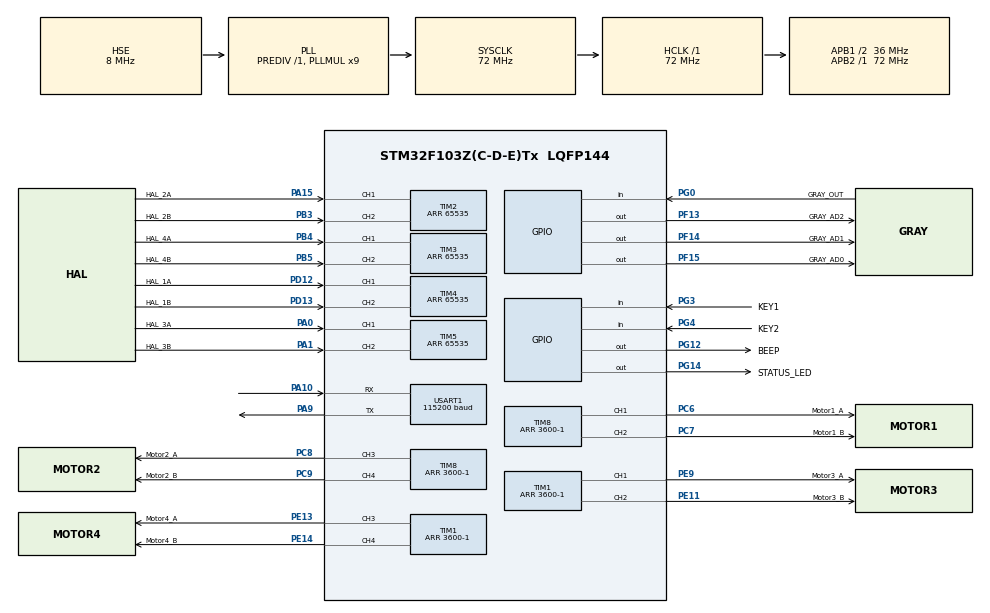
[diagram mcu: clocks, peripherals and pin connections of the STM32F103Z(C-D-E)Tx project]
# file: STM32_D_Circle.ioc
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Mcu.Family=STM32F1
Mcu.Name=STM32F103Z(C-D-E)Tx
Mcu.Package=LQFP144
NVIC.PriorityGroup=NVIC_PRIORITYGROUP_4
NVIC.USART1_IRQn=true\:1\:0\:false\:false\:true\:true\:true\:true
OSC_IN.Mode=HSE-External-Oscillator
OSC_IN.Signal=RCC_OSC_IN
OSC_OUT.Mode=HSE-External-Oscillator
OSC_OUT.Signal=RCC_OSC_OUT
PA0-WKUP.GPIO_Label=HAL_3A
PA0-WKUP.Signal=S_TIM5_CH1
PA1.GPIO_Label=HAL_3B
PA1.Signal=S_TIM5_CH2
PA10.Mode=Asynchronous
PA10.Signal=USART1_RX
PA13.Mode=Serial_Wire
PA13.Signal=SYS_JTMS-SWDIO
PA14.Mode=Serial_Wire
PA14.Signal=SYS_JTCK-SWCLK
PA15.GPIO_Label=HAL_2A
PA15.Signal=S_TIM2_CH1_ETR
PA9.Mode=Asynchronous
PA9.Signal=USART1_TX
PB3.GPIO_Label=HAL_2B
PB3.Signal=S_TIM2_CH2
PB4.GPIO_Label=HAL_4A
PB4.Signal=S_TIM3_CH1
PB5.GPIO_Label=HAL_4B
PB5.Signal=S_TIM3_CH2
PC6.GPIO_Label=Motor1_A
PC6.Signal=S_TIM8_CH1
PC7.GPIO_Label=Motor1_B
PC7.Signal=S_TIM8_CH2
PC8.GPIO_Label=Motor2_A
PC8.Signal=S_TIM8_CH3
PC9.GPIO_Label=Motor2_B
PC9.Signal=S_TIM8_CH4
PD12.GPIO_Label=HAL_1A
PD12.Signal=S_TIM4_CH1
PD13.GPIO_Label=HAL_1B
PD13.Signal=S_TIM4_CH2
PE11.GPIO_Label=Motor3_B
PE11.Signal=S_TIM1_CH2
PE13.GPIO_Label=Motor4_A
PE13.Signal=S_TIM1_CH3
PE14.GPIO_Label=Motor4_B
PE14.Signal=S_TIM1_CH4
PE9.GPIO_Label=Motor3_A
PE9.Signal=S_TIM1_CH1
PF13.GPIO_Label=GRAY_AD2
PF13.Signal=GPIO_Output
PF14.GPIO_Label=GRAY_AD1
PF14.Signal=GPIO_Output
PF15.GPIO_Label=GRAY_AD0
PF15.Signal=GPIO_Output
PG0.GPIO_Label=GRAY_OUT
PG0.Signal=GPIO_Input
PG12.GPIO_Label=BEEP
PG12.Signal=GPIO_Output
PG14.GPIO_Label=STATUS_LED
PG14.Signal=GPIO_Output
PG3.GPIO_Label=KEY1
PG3.Signal=GPIO_Input
PG4.GPIO_Label=KEY2
PG4.Signal=GPIO_Input
ProjectManager.HeapSize=0x200
ProjectManager.StackSize=0x1000
ProjectManager.TargetToolchain=MDK-ARM V5.32
RCC.ADCPresc=RCC_ADCPCLK2_DIV6
RCC.AHBFreq_Value=72000000
RCC.APB1CLKDivider=RCC_HCLK_DIV2
RCC.APB1Freq_Value=36000000
RCC.APB1TimFreq_Value=72000000
RCC.APB2Freq_Value=72000000
RCC.APB2TimFreq_Value=72000000
RCC.HCLKFreq_Value=72000000
RCC.PLLMUL=RCC_PLL_MUL9
RCC.PLLSourceVirtual=RCC_PLLSOURCE_HSE
RCC.SYSCLKFreq_VALUE=72000000
RCC.SYSCLKSource=RCC_SYSCLKSOURCE_PLLCLK
RCC.USBFreq_Value=72000000
SH.S_TIM1_CH1.0=TIM1_CH1,PWM Generation1 CH1
SH.S_TIM1_CH2.0=TIM1_CH2,PWM Generation2 CH2
SH.S_TIM1_CH3.0=TIM1_CH3,PWM Generation3 CH3
SH.S_TIM1_CH4.0=TIM1_CH4,PWM Generation4 CH4
SH.S_TIM2_CH1_ETR.0=TIM2_CH1,Encoder_Interface
SH.S_TIM2_CH2.0=TIM2_CH2,Encoder_Interface
SH.S_TIM3_CH1.0=TIM3_CH1,Encoder_Interface
SH.S_TIM3_CH2.0=TIM3_CH2,Encoder_Interface
SH.S_TIM4_CH1.0=TIM4_CH1,Encoder_Interface
SH.S_TIM4_CH2.0=TIM4_CH2,Encoder_Interface
SH.S_TIM5_CH1.0=TIM5_CH1,Encoder_Interface
SH.S_TIM5_CH2.0=TIM5_CH2,Encoder_Interface
SH.S_TIM8_CH1.0=TIM8_CH1,PWM Generation1 CH1
SH.S_TIM8_CH2.0=TIM8_CH2,PWM Generation2 CH2
SH.S_TIM8_CH3.0=TIM8_CH3,PWM Generation3 CH3
SH.S_TIM8_CH4.0=TIM8_CH4,PWM Generation4 CH4
TIM1.AutoReloadPreload=TIM_AUTORELOAD_PRELOAD_ENABLE
TIM1.Channel-PWM\ Generation1\ CH1=TIM_CHANNEL_1
TIM1.Channel-PWM\ Generation2\ CH2=TIM_CHANNEL_2
TIM1.Channel-PWM\ Generation3\ CH3=TIM_CHANNEL_3
TIM1.Channel-PWM\ Generation4\ CH4=TIM_CHANNEL_4
TIM1.Period=3600-1
TIM2.EncoderMode=TIM_ENCODERMODE_TI12
TIM2.IC1Filter=6
TIM2.IC2Filter=6
TIM2.Period=65535
TIM3.EncoderMode=TIM_ENCODERMODE_TI12
TIM3.IC1Filter=6
TIM3.IC2Filter=6
TIM3.Period=65535
TIM4.EncoderMode=TIM_ENCODERMODE_TI12
TIM4.IC1Filter=6
TIM4.IC2Filter=6
TIM4.Period=65535
TIM5.EncoderMode=TIM_ENCODERMODE_TI12
TIM5.IC1Filter=6
TIM5.IC2Filter=6
TIM5.Period=65535
TIM8.AutoReloadPreload=TIM_AUTORELOAD_PRELOAD_ENABLE
TIM8.Channel-PWM\ Generation1\ CH1=TIM_CHANNEL_1
TIM8.Channel-PWM\ Generation2\ CH2=TIM_CHANNEL_2
TIM8.Channel-PWM\ Generation3\ CH3=TIM_CHANNEL_3
TIM8.Channel-PWM\ Generation4\ CH4=TIM_CHANNEL_4
TIM8.Period=3600-1
USART1.BaudRate=115200
VP_TIM1_VS_ClockSourceINT.Mode=Internal
VP_TIM8_VS_ClockSourceINT.Mode=Internal
board=custom

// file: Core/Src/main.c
/* USER CODE BEGIN Header */
/* One clockwise lap, then stop. No motion is requested at power-on. */
/* USER CODE END Header */
#include "main.h"
#include "gpio.h"
#include "tim.h"
#include "usart.h"
/* USER CODE BEGIN Includes */
#include "app_run.h"
/* USER CODE END Includes */
void SystemClock_Config(void);

int main(void)
{
    HAL_Init();
    SystemClock_Config();
    MX_GPIO_Init();
    MX_TIM1_Init();
    MX_TIM2_Init();
    MX_TIM3_Init();
    MX_TIM4_Init();
    MX_TIM5_Init();
    MX_TIM8_Init();
    MX_USART1_UART_Init();
    /* USER CODE BEGIN 2 */
    App_Init();
    /* USER CODE END 2 */
    while (1)
    {
        /* USER CODE BEGIN 3 */
        App_Poll();
        /* USER CODE END 3 */
    }
}

void SystemClock_Config(void)
{
    RCC_OscInitTypeDef osc = {0};
    RCC_ClkInitTypeDef clk = {0};
    RCC_PeriphCLKInitTypeDef peripheral = {0};
    osc.OscillatorType = RCC_OSCILLATORTYPE_HSE;
    osc.HSEState = RCC_HSE_ON;
    osc.HSEPredivValue = RCC_HSE_PREDIV_DIV1;
    osc.HSIState = RCC_HSI_ON;
    osc.PLL.PLLState = RCC_PLL_ON;
    osc.PLL.PLLSource = RCC_PLLSOURCE_HSE;
    osc.PLL.PLLMUL = RCC_PLL_MUL9;
    if (HAL_RCC_OscConfig(&osc) != HAL_OK) Error_Handler();
    clk.ClockType = RCC_CLOCKTYPE_SYSCLK | RCC_CLOCKTYPE_HCLK |
                    RCC_CLOCKTYPE_PCLK1 | RCC_CLOCKTYPE_PCLK2;
    clk.SYSCLKSource = RCC_SYSCLKSOURCE_PLLCLK;
    clk.AHBCLKDivider = RCC_SYSCLK_DIV1;
    clk.APB1CLKDivider = RCC_HCLK_DIV2;
    clk.APB2CLKDivider = RCC_HCLK_DIV1;
    if (HAL_RCC_ClockConfig(&clk, FLASH_LATENCY_2) != HAL_OK) Error_Handler();
    peripheral.PeriphClockSelection = RCC_PERIPHCLK_ADC;
    peripheral.AdcClockSelection = RCC_ADCPCLK2_DIV6;
    if (HAL_RCCEx_PeriphCLKConfig(&peripheral) != HAL_OK) Error_Handler();
}

void Error_Handler(void)
{
    /* USER CODE BEGIN Error_Handler_Debug */
    __disable_irq();
    __HAL_RCC_TIM1_CLK_ENABLE();
    __HAL_RCC_TIM8_CLK_ENABLE();
    TIM1->BDTR &= ~TIM_BDTR_MOE;
    TIM8->BDTR &= ~TIM_BDTR_MOE;
    while (1) { }
    /* USER CODE END Error_Handler_Debug */
}
